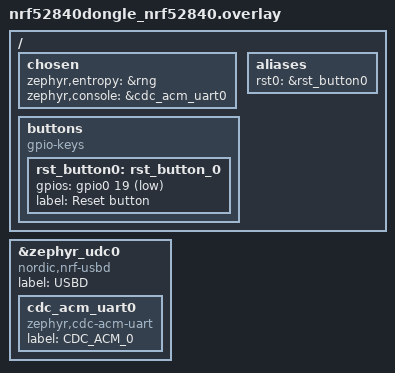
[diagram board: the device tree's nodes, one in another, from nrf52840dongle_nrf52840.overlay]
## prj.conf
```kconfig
#
# Copyright (c) 2020 Nordic Semiconductor ASA
#
# SPDX-License-Identifier: LicenseRef-Nordic-5-Clause
#

CONFIG_NCS_SAMPLES_DEFAULTS=y

CONFIG_UART_INTERRUPT_DRIVEN=y
CONFIG_SERIAL=y
CONFIG_GPIO=y

# Make sure printk is not printing to the UART console
CONFIG_CONSOLE=y
CONFIG_UART_CONSOLE=y


# Enable DK LED and Buttons library
CONFIG_DK_LIBRARY=y

# This example requires more workqueue stack
CONFIG_SYSTEM_WORKQUEUE_STACK_SIZE=2048

##############

CONFIG_USB_DEVICE_STACK=y
CONFIG_USB_DEVICE_DRIVER=y
CONFIG_USB_DEVICE_PRODUCT="Zephyr USB console sample"
CONFIG_USB_DEVICE_MANUFACTURER="Nordic Semiconductor ASA"
CONFIG_USB_DEVICE_VID=0x1915
CONFIG_USB_DEVICE_PID=0x0100

CONFIG_UART_LINE_CTRL=y
CONFIG_USB_CDC_ACM_LOG_LEVEL_OFF=y

# Since the default LOG_MODE_MINIMAL is synchronous, it will mess with the USB
# driver/subsys. Use the deferred mode instead.
CONFIG_LOG_MODE_DEFERRED=y
```

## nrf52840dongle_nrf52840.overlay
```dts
/*
 * Copyright (c) 2021 Nordic Semiconductor ASA
 *
 * SPDX-License-Identifier: LicenseRef-Nordic-5-Clause
 */

 / {
	chosen {
		zephyr,entropy = &rng;
		zephyr,console = &cdc_acm_uart0;
	};
/*
	pwmleds {
		pwm_led3: pwm_led_3 {
			pwms = <&pwm0 12>;
		};
	};
*/

	buttons {
		compatible = "gpio-keys";
		rst_button0: rst_button_0 {
			gpios = <&gpio0 19 (GPIO_PULL_UP | GPIO_ACTIVE_LOW)>;
			label = "Reset button";
		};
	};

	aliases {
		rst0 = &rst_button0;
	};
};


&zephyr_udc0 {
	compatible = "nordic,nrf-usbd";
	status = "okay";
	label = "USBD";
	cdc_acm_uart0: cdc_acm_uart0 {
		compatible = "zephyr,cdc-acm-uart";
		label = "CDC_ACM_0";
	};
};
```

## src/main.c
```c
#include <zephyr/kernel.h>

#include <zephyr/sys/printk.h>
#include <zephyr/usb/usb_device.h>
#include <zephyr/drivers/uart.h>

BUILD_ASSERT(DT_NODE_HAS_COMPAT(DT_CHOSEN(zephyr_console), zephyr_cdc_acm_uart),
	     "Console device is not ACM CDC UART device");

int main(void){
	const struct device *dev = DEVICE_DT_GET(DT_CHOSEN(zephyr_console));
	uint32_t dtr = 0;

	if (usb_enable(NULL)) {
		return;
	}

	/* Poll if the DTR flag was set */
	while (!dtr) {
		uart_line_ctrl_get(dev, UART_LINE_CTRL_DTR, &dtr);
		/* Give CPU resources to low priority threads. */
		k_sleep(K_MSEC(100));
	}

	int console_init(void);
	printk("hello world\r\n");

}
```
